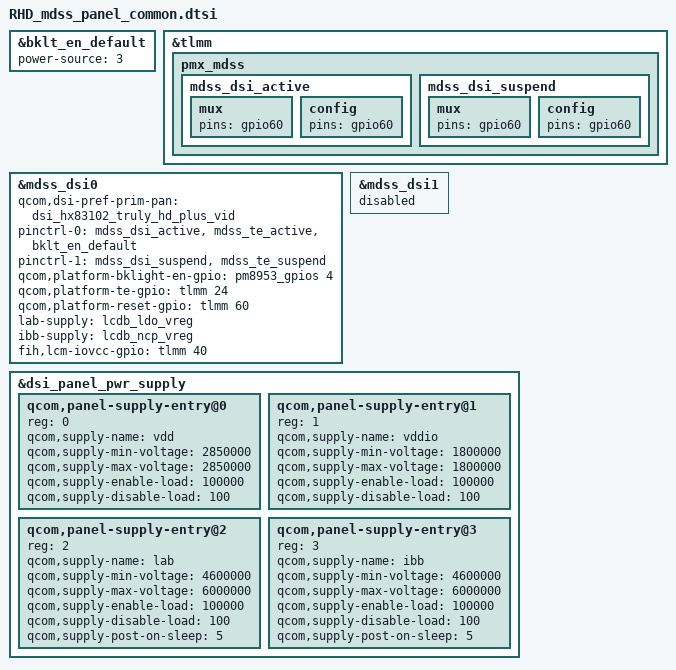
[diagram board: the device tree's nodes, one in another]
/* Copyright (c) 2018, The Linux Foundation. All rights reserved.
 *
 * This program is free software; you can redistribute it and/or modify
 * it under the terms of the GNU General Public License version 2 and
 * only version 2 as published by the Free Software Foundation.
 *
 * This program is distributed in the hope that it will be useful,
 * but WITHOUT ANY WARRANTY; without even the implied warranty of
 * MERCHANTABILITY or FITNESS FOR A PARTICULAR PURPOSE.  See the
 * GNU General Public License for more details.
 */

&bklt_en_default {
	power-source = <3>;
};

&tlmm {
	pmx_mdss {
		mdss_dsi_active: mdss_dsi_active {
			mux {
				pins = "gpio60";
			};
			config {
				pins = "gpio60";
			};
		};
		mdss_dsi_suspend: mdss_dsi_suspend {
			mux {
				pins = "gpio60";
			};
			config {
				pins = "gpio60";
			};
		};
	};
};

&mdss_dsi0 {
	qcom,dsi-pref-prim-pan = <&dsi_hx83102_truly_hd_plus_vid>;
	pinctrl-names = "mdss_default", "mdss_sleep";
	pinctrl-0 = <&mdss_dsi_active &mdss_te_active &bklt_en_default>;
	pinctrl-1 = <&mdss_dsi_suspend &mdss_te_suspend>;

	qcom,platform-bklight-en-gpio = <&pm8953_gpios 4 0>;
	qcom,platform-te-gpio = <&tlmm 24 0>;
	qcom,platform-reset-gpio = <&tlmm 60 0>;
	lab-supply = <&lcdb_ldo_vreg>;
	ibb-supply = <&lcdb_ncp_vreg>;
	fih,lcm-iovcc-gpio =  <&tlmm 40 0>;
};

&mdss_dsi1 {
	status = "disabled";
};

&dsi_panel_pwr_supply {
	#address-cells = <1>;
	#size-cells = <0>;

	qcom,panel-supply-entry@0 {
		reg = <0>;
		qcom,supply-name = "vdd";
		qcom,supply-min-voltage = <2850000>;
		qcom,supply-max-voltage = <2850000>;
		qcom,supply-enable-load = <100000>;
		qcom,supply-disable-load = <100>;
	};

	qcom,panel-supply-entry@1 {
		reg = <1>;
		qcom,supply-name = "vddio";
		qcom,supply-min-voltage = <1800000>;
		qcom,supply-max-voltage = <1800000>;
		qcom,supply-enable-load = <100000>;
		qcom,supply-disable-load = <100>;
	};

	qcom,panel-supply-entry@2 {
		reg = <2>;
		qcom,supply-name = "lab";
		qcom,supply-min-voltage = <4600000>;
		qcom,supply-max-voltage = <6000000>;
		qcom,supply-enable-load = <100000>;
		qcom,supply-disable-load = <100>;
		qcom,supply-post-on-sleep = <5>;
	};

	qcom,panel-supply-entry@3 {
		reg = <3>;
		qcom,supply-name = "ibb";
		qcom,supply-min-voltage = <4600000>;
		qcom,supply-max-voltage = <6000000>;
		qcom,supply-enable-load = <100000>;
		qcom,supply-disable-load = <100>;
		qcom,supply-post-on-sleep = <5>;
	};
};
